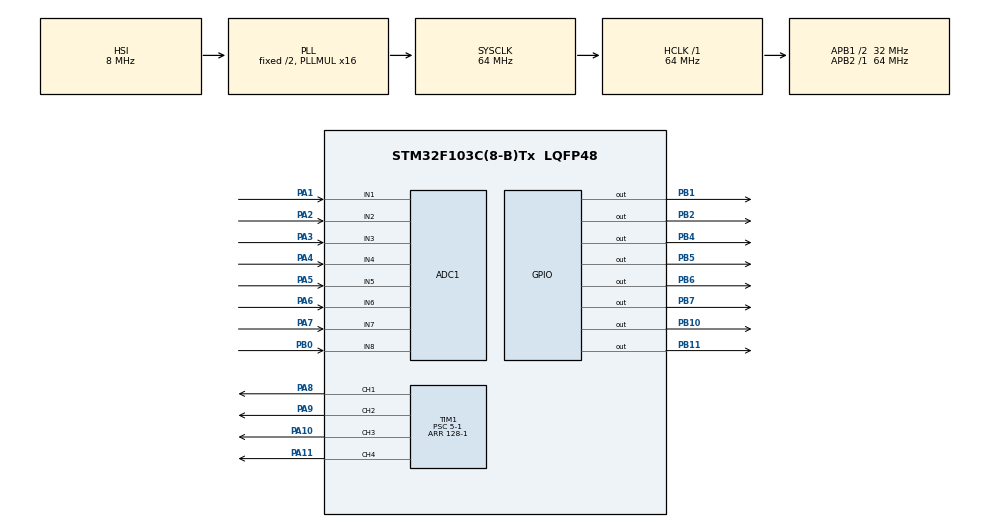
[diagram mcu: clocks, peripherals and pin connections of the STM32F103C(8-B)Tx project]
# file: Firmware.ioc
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ADC1.Channel-34\#ChannelRegularConversion=ADC_CHANNEL_1
ADC1.Channel-35\#ChannelRegularConversion=ADC_CHANNEL_2
ADC1.Channel-36\#ChannelRegularConversion=ADC_CHANNEL_3
ADC1.Channel-37\#ChannelRegularConversion=ADC_CHANNEL_4
ADC1.Channel-38\#ChannelRegularConversion=ADC_CHANNEL_5
ADC1.Channel-39\#ChannelRegularConversion=ADC_CHANNEL_6
ADC1.Channel-40\#ChannelRegularConversion=ADC_CHANNEL_7
ADC1.Channel-41\#ChannelRegularConversion=ADC_CHANNEL_8
ADC1.ContinuousConvMode=ENABLE
ADC1.EnableInjectedConversion=DISABLE
ADC1.EnableRegularConversion=ENABLE
ADC1.InjNumberOfConversion=0
ADC1.NbrOfConversion=8
ADC1.NbrOfConversionFlag=1
ADC1.Rank-34\#ChannelRegularConversion=1
ADC1.Rank-35\#ChannelRegularConversion=2
ADC1.Rank-36\#ChannelRegularConversion=3
ADC1.Rank-37\#ChannelRegularConversion=4
ADC1.Rank-38\#ChannelRegularConversion=5
ADC1.Rank-39\#ChannelRegularConversion=6
ADC1.Rank-40\#ChannelRegularConversion=7
ADC1.Rank-41\#ChannelRegularConversion=8
ADC1.SamplingTime-34\#ChannelRegularConversion=ADC_SAMPLETIME_1CYCLE_5
ADC1.SamplingTime-35\#ChannelRegularConversion=ADC_SAMPLETIME_1CYCLE_5
ADC1.SamplingTime-36\#ChannelRegularConversion=ADC_SAMPLETIME_1CYCLE_5
ADC1.SamplingTime-37\#ChannelRegularConversion=ADC_SAMPLETIME_1CYCLE_5
ADC1.SamplingTime-38\#ChannelRegularConversion=ADC_SAMPLETIME_1CYCLE_5
ADC1.SamplingTime-39\#ChannelRegularConversion=ADC_SAMPLETIME_1CYCLE_5
ADC1.SamplingTime-40\#ChannelRegularConversion=ADC_SAMPLETIME_1CYCLE_5
ADC1.SamplingTime-41\#ChannelRegularConversion=ADC_SAMPLETIME_1CYCLE_5
ADC1.master=1
Dma.ADC1.0.Direction=DMA_PERIPH_TO_MEMORY
Dma.ADC1.0.Instance=DMA1_Channel1
Dma.ADC1.0.MemDataAlignment=DMA_MDATAALIGN_HALFWORD
Dma.ADC1.0.MemInc=DMA_MINC_ENABLE
Dma.ADC1.0.Mode=DMA_CIRCULAR
Dma.ADC1.0.PeriphDataAlignment=DMA_PDATAALIGN_HALFWORD
Dma.ADC1.0.PeriphInc=DMA_PINC_DISABLE
Dma.ADC1.0.Priority=DMA_PRIORITY_LOW
Dma.Request0=ADC1
Mcu.Family=STM32F1
Mcu.Name=STM32F103C(8-B)Tx
Mcu.Package=LQFP48
NVIC.ADC1_2_IRQn=true\:0\:0\:false\:false\:true\:true\:true\:true
NVIC.DMA1_Channel1_IRQn=true\:0\:0\:false\:false\:true\:false\:true\:true
NVIC.PriorityGroup=NVIC_PRIORITYGROUP_4
NVIC.TIM2_IRQn=true\:0\:0\:false\:false\:true\:true\:true\:true
NVIC.TIM3_IRQn=true\:0\:0\:false\:false\:true\:true\:true\:true
NVIC.TIM4_IRQn=true\:0\:0\:false\:false\:true\:true\:true\:true
PA1.Signal=ADCx_IN1
PA10.Signal=S_TIM1_CH3
PA11.Signal=S_TIM1_CH4
PA13.Mode=Serial_Wire
PA13.Signal=SYS_JTMS-SWDIO
PA14.Mode=Serial_Wire
PA14.Signal=SYS_JTCK-SWCLK
PA2.Signal=ADCx_IN2
PA3.Signal=ADCx_IN3
PA4.Signal=ADCx_IN4
PA5.Signal=ADCx_IN5
PA6.Signal=ADCx_IN6
PA7.Signal=ADCx_IN7
PA8.Signal=S_TIM1_CH1
PA9.Signal=S_TIM1_CH2
PB0.Signal=ADCx_IN8
PB1.Signal=GPIO_Output
PB10.Signal=GPIO_Output
PB11.Signal=GPIO_Output
PB2.Signal=GPIO_Output
PB4.Signal=GPIO_Output
PB5.Signal=GPIO_Output
PB6.Signal=GPIO_Output
PB7.Signal=GPIO_Output
ProjectManager.HeapSize=0x200
ProjectManager.StackSize=0x400
ProjectManager.TargetToolchain=MDK-ARM V5.32
RCC.ADCPresc=RCC_ADCPCLK2_DIV6
RCC.AHBFreq_Value=64000000
RCC.APB1CLKDivider=RCC_HCLK_DIV2
RCC.APB1Freq_Value=32000000
RCC.APB1TimFreq_Value=64000000
RCC.APB2Freq_Value=64000000
RCC.APB2TimFreq_Value=64000000
RCC.HCLKFreq_Value=64000000
RCC.PLLMUL=RCC_PLL_MUL16
RCC.SYSCLKFreq_VALUE=64000000
RCC.SYSCLKSource=RCC_SYSCLKSOURCE_PLLCLK
RCC.USBFreq_Value=64000000
SH.ADCx_IN1.0=ADC1_IN1,IN1
SH.ADCx_IN2.0=ADC1_IN2,IN2
SH.ADCx_IN3.0=ADC1_IN3,IN3
SH.ADCx_IN4.0=ADC1_IN4,IN4
SH.ADCx_IN5.0=ADC1_IN5,IN5
SH.ADCx_IN6.0=ADC1_IN6,IN6
SH.ADCx_IN7.0=ADC1_IN7,IN7
SH.ADCx_IN8.0=ADC1_IN8,IN8
SH.S_TIM1_CH1.0=TIM1_CH1,PWM Generation1 CH1
SH.S_TIM1_CH2.0=TIM1_CH2,PWM Generation2 CH2
SH.S_TIM1_CH3.0=TIM1_CH3,PWM Generation3 CH3
SH.S_TIM1_CH4.0=TIM1_CH4,PWM Generation4 CH4
TIM1.AutoReloadPreload=TIM_AUTORELOAD_PRELOAD_ENABLE
TIM1.Channel-PWM\ Generation1\ CH1=TIM_CHANNEL_1
TIM1.Channel-PWM\ Generation2\ CH2=TIM_CHANNEL_2
TIM1.Channel-PWM\ Generation3\ CH3=TIM_CHANNEL_3
TIM1.Channel-PWM\ Generation4\ CH4=TIM_CHANNEL_4
TIM1.Period=128-1
TIM1.Prescaler=5-1
TIM2.AutoReloadPreload=TIM_AUTORELOAD_PRELOAD_ENABLE
TIM2.Channel-PWM\ Generation1\ No\ Output=TIM_CHANNEL_1
TIM2.Period=1000-1
TIM2.Prescaler=64-1
TIM3.AutoReloadPreload=TIM_AUTORELOAD_PRELOAD_ENABLE
TIM3.Channel-PWM\ Generation1\ No\ Output=TIM_CHANNEL_1
TIM3.Period=100-1
TIM3.Prescaler=64-1
TIM4.Channel-Output\ Compare1\ No\ Output=TIM_CHANNEL_1
TIM4.Period=2-1
TIM4.Prescaler=32-1
VP_TIM2_VS_no_output1.Mode=PWM Generation1 No Output
VP_TIM3_VS_no_output1.Mode=PWM Generation1 No Output
VP_TIM4_VS_no_output1.Mode=Output Compare1 No Output
board=custom

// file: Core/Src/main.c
/* USER CODE BEGIN Header */
/**
  ******************************************************************************
  * @file           : main.c
  * @brief          : Main program body
  ******************************************************************************
  * @attention
  *
  * Copyright (c) 2025 STMicroelectronics.
  * All rights reserved.
  *
  * This software is licensed under terms that can be found in the LICENSE file
  * in the root directory of this software component.
  * If no LICENSE file comes with this software, it is provided AS-IS.
  *
  ******************************************************************************
  */
/* USER CODE END Header */
#include "main.h"
#include "adc.h"
#include "dma.h"
#include "tim.h"
#include "gpio.h"

/* USER CODE BEGIN Includes */
#include "function.h"
/* USER CODE END Includes */

void SystemClock_Config(void);

int main(void)
{

  /* MCU Configuration--------------------------------------------------------*/

  /* Reset of all peripherals, Initializes the Flash interface and the Systick. */
  HAL_Init();

  /* Configure the system clock */
  SystemClock_Config();

  /* Initialize all configured peripherals */
  MX_GPIO_Init();
  MX_DMA_Init();
  MX_ADC1_Init();
  MX_TIM1_Init();
  MX_TIM2_Init();
  MX_TIM3_Init();
  MX_TIM4_Init();
  /* USER CODE BEGIN 2 */
	led_init();							//init LED,actually blink led for 5 times every time when power up
	HAL_TIM_PWM_Start(&htim1 ,TIM_CHANNEL_ALL);
	__HAL_TIM_SetCompare(&htim1,TIM_CHANNEL_ALL,0);//close 5v npn diodes
	HAL_GPIO_WritePin(GPIOB,GPIO_PIN_1,GPIO_PIN_RESET);
	HAL_GPIO_WritePin(GPIOB,GPIO_PIN_2,GPIO_PIN_RESET);
	HAL_GPIO_WritePin(GPIOB,GPIO_PIN_10,GPIO_PIN_RESET);
	HAL_GPIO_WritePin(GPIOB,GPIO_PIN_11,GPIO_PIN_RESET);
	tim_init_it();					//initiallize tim

  /* USER CODE END 2 */

  /* Infinite loop */
  while (1)
  {

  }
}

void SystemClock_Config(void)
{
  RCC_OscInitTypeDef RCC_OscInitStruct = {0};
  RCC_ClkInitTypeDef RCC_ClkInitStruct = {0};
  RCC_PeriphCLKInitTypeDef PeriphClkInit = {0};

  /** Initializes the RCC Oscillators according to the specified parameters
  * in the RCC_OscInitTypeDef structure.
  */
  RCC_OscInitStruct.OscillatorType = RCC_OSCILLATORTYPE_HSI;
  RCC_OscInitStruct.HSIState = RCC_HSI_ON;
  RCC_OscInitStruct.HSICalibrationValue = RCC_HSICALIBRATION_DEFAULT;
  RCC_OscInitStruct.PLL.PLLState = RCC_PLL_ON;
  RCC_OscInitStruct.PLL.PLLSource = RCC_PLLSOURCE_HSI_DIV2;
  RCC_OscInitStruct.PLL.PLLMUL = RCC_PLL_MUL16;
  if (HAL_RCC_OscConfig(&RCC_OscInitStruct) != HAL_OK)
  {
    Error_Handler();
  }

  /** Initializes the CPU, AHB and APB buses clocks
  */
  RCC_ClkInitStruct.ClockType = RCC_CLOCKTYPE_HCLK|RCC_CLOCKTYPE_SYSCLK
                              |RCC_CLOCKTYPE_PCLK1|RCC_CLOCKTYPE_PCLK2;
  RCC_ClkInitStruct.SYSCLKSource = RCC_SYSCLKSOURCE_PLLCLK;
  RCC_ClkInitStruct.AHBCLKDivider = RCC_SYSCLK_DIV1;
  RCC_ClkInitStruct.APB1CLKDivider = RCC_HCLK_DIV2;
  RCC_ClkInitStruct.APB2CLKDivider = RCC_HCLK_DIV1;

  if (HAL_RCC_ClockConfig(&RCC_ClkInitStruct, FLASH_LATENCY_2) != HAL_OK)
  {
    Error_Handler();
  }
  PeriphClkInit.PeriphClockSelection = RCC_PERIPHCLK_ADC;
  PeriphClkInit.AdcClockSelection = RCC_ADCPCLK2_DIV6;
  if (HAL_RCCEx_PeriphCLKConfig(&PeriphClkInit) != HAL_OK)
  {
    Error_Handler();
  }
}

void Error_Handler(void)
{
  __disable_irq();
  while (1)
  {
  }
}
